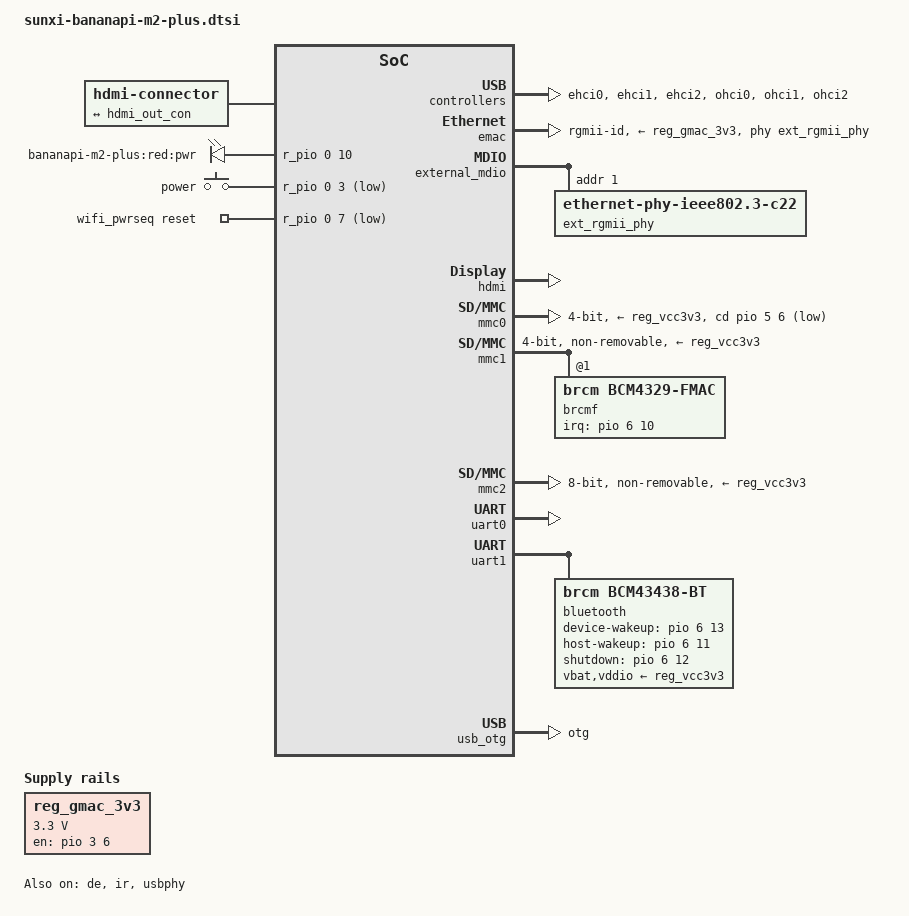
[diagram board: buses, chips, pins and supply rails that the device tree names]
#include "sunxi-common-regulators.dtsi"
#include <dt-bindings/gpio/gpio.h>
#include <dt-bindings/input/input.h>
/ {
	aliases {
		ethernet0 = &emac;
		serial0 = &uart0;
		serial1 = &uart1;
	};
	chosen {
		stdout-path = "serial0:115200n8";
	};
	connector {
		compatible = "hdmi-connector";
		type = "a";
		port {
			hdmi_con_in: endpoint {
				remote-endpoint = <&hdmi_out_con>;
			};
		};
	};
	leds {
		compatible = "gpio-leds";
		pwr_led {
			label = "bananapi-m2-plus:red:pwr";
			gpios = <&r_pio 0 10 GPIO_ACTIVE_HIGH>;  
			default-state = "on";
		};
	};
	gpio-keys {
		compatible = "gpio-keys";
		switch-4 {
			label = "power";
			linux,code = <KEY_POWER>;
			gpios = <&r_pio 0 3 GPIO_ACTIVE_LOW>;
			wakeup-source;
		};
	};
	reg_gmac_3v3: gmac-3v3 {
		compatible = "regulator-fixed";
		regulator-name = "gmac-3v3";
		regulator-min-microvolt = <3300000>;
		regulator-max-microvolt = <3300000>;
		startup-delay-us = <100000>;
		enable-active-high;
		gpio = <&pio 3 6 GPIO_ACTIVE_HIGH>;
	};
	wifi_pwrseq: wifi_pwrseq {
		compatible = "mmc-pwrseq-simple";
		reset-gpios = <&r_pio 0 7 GPIO_ACTIVE_LOW>;  
		clocks = <&rtc CLK_OSC32K_FANOUT>;
		clock-names = "ext_clock";
	};
};
&de {
	status = "okay";
};
&ehci0 {
	status = "okay";
};
&ehci1 {
	status = "okay";
};
&ehci2 {
	status = "okay";
};
&emac {
	pinctrl-names = "default";
	pinctrl-0 = <&emac_rgmii_pins>;
	phy-supply = <&reg_gmac_3v3>;
	phy-handle = <&ext_rgmii_phy>;
	phy-mode = "rgmii-id";
	status = "okay";
};
&external_mdio {
	ext_rgmii_phy: ethernet-phy@1 {
		compatible = "ethernet-phy-ieee802.3-c22";
		reg = <1>;
	};
};
&hdmi {
	status = "okay";
};
&hdmi_out {
	hdmi_out_con: endpoint {
		remote-endpoint = <&hdmi_con_in>;
	};
};
&ir {
	pinctrl-names = "default";
	pinctrl-0 = <&r_ir_rx_pin>;
	status = "okay";
};
&mmc0 {
	vmmc-supply = <&reg_vcc3v3>;
	bus-width = <4>;
	cd-gpios = <&pio 5 6 GPIO_ACTIVE_LOW>;  
	status = "okay";
};
&mmc1 {
	vmmc-supply = <&reg_vcc3v3>;
	vqmmc-supply = <&reg_vcc3v3>;
	mmc-pwrseq = <&wifi_pwrseq>;
	bus-width = <4>;
	non-removable;
	status = "okay";
	brcmf: wifi@1 {
		reg = <1>;
		compatible = "brcm,bcm4329-fmac";
		interrupt-parent = <&pio>;
		interrupts = <6 10 IRQ_TYPE_LEVEL_LOW>;  
		interrupt-names = "host-wake";
	};
};
&mmc2 {
	pinctrl-names = "default";
	pinctrl-0 = <&mmc2_8bit_pins>;
	vmmc-supply = <&reg_vcc3v3>;
	vqmmc-supply = <&reg_vcc3v3>;
	bus-width = <8>;
	non-removable;
	status = "okay";
};
&ohci0 {
	status = "okay";
};
&ohci1 {
	status = "okay";
};
&ohci2 {
	status = "okay";
};
&reg_usb0_vbus {
	gpio = <&pio 3 11 GPIO_ACTIVE_HIGH>;  
	status = "okay";
};
&uart0 {
	pinctrl-names = "default";
	pinctrl-0 = <&uart0_pa_pins>;
	status = "okay";
};
&uart1 {
	pinctrl-names = "default";
	pinctrl-0 = <&uart1_pins>, <&uart1_rts_cts_pins>;
	uart-has-rtscts;
	status = "okay";
	bluetooth {
		compatible = "brcm,bcm43438-bt";
		max-speed = <1500000>;
		clocks = <&rtc CLK_OSC32K_FANOUT>;
		clock-names = "lpo";
		vbat-supply = <&reg_vcc3v3>;
		vddio-supply = <&reg_vcc3v3>;
		device-wakeup-gpios = <&pio 6 13 GPIO_ACTIVE_HIGH>;  
		host-wakeup-gpios = <&pio 6 11 GPIO_ACTIVE_HIGH>;  
		shutdown-gpios = <&pio 6 12 GPIO_ACTIVE_HIGH>;  
	};
};
&usb_otg {
	dr_mode = "otg";
	status = "okay";
};
&usbphy {
	usb0_id_det-gpios = <&r_pio 0 6 GPIO_ACTIVE_HIGH>;  
	usb0_vbus-supply = <&reg_usb0_vbus>;
	status = "okay";
};
